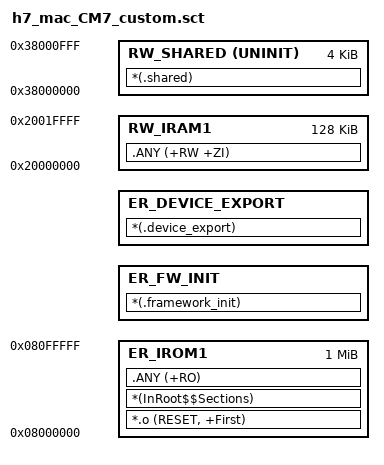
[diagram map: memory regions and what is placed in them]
LR_IROM1 0x08000000 0x00100000
{
    ER_IROM1 0x08000000 0x00100000
    {
        *.o (RESET, +First)
        *(InRoot$$Sections)
        .ANY (+RO)
    }

    ER_FW_INIT +0
    {
        *(.framework_init)
    }

   ER_DEVICE_EXPORT +0
   {
        *(.device_export)
    }

    RW_SHARED 0x38000000 UNINIT 0x00001000
    {
        *(.shared)
    }

    RW_IRAM1 0x20000000 0x00020000
    {
        .ANY (+RW +ZI)
    }
}
